VERSION ""

NS_ :

BS_:

BU_:

BO_ 3221225472 VECTOR__INDEPENDENT_SIG_MSG: 0 Vector__XXX
 SG_ NewSignal_0005 : 32|8@1+ (1,0) [0|0] "" Vector__XXX
 SG_ NewSignal_0007 : 48|8@1+ (1,0) [0|0] "" Vector__XXX
 SG_ NewSignal_0010 : 8|8@1+ (1,0) [0|0] "" Vector__XXX

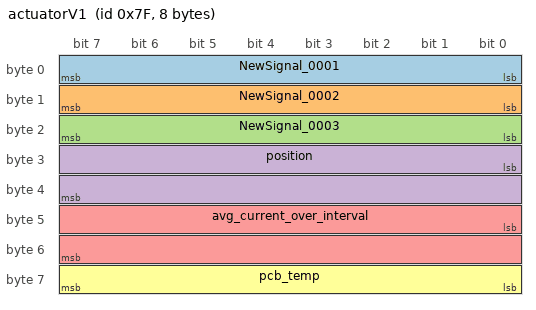
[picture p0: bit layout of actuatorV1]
BO_ 127 actuatorV1: 8 Vector__XXX
 SG_ NewSignal_0001 : 0|8@1+ (1,0) [0|0] "" Vector__XXX
 SG_ NewSignal_0002 : 8|8@1+ (1,0) [0|0] "" Vector__XXX
 SG_ NewSignal_0003 : 16|8@1+ (1,0) [0|0] "" Vector__XXX
 SG_ position : 24|16@1+ (1,0) [0|0] "" Vector__XXX
 SG_ avg_current_over_interval : 40|16@1+ (1,0) [0|0] "" Vector__XXX
 SG_ pcb_temp : 56|8@1+ (1,0) [0|0] "" Vector__XXX

BO_ 3 NewMessage_0002: 2 Vector__XXX
 SG_ maybe_position_send : 0|16@1+ (1,0) [0|0] "" Vector__XXX
